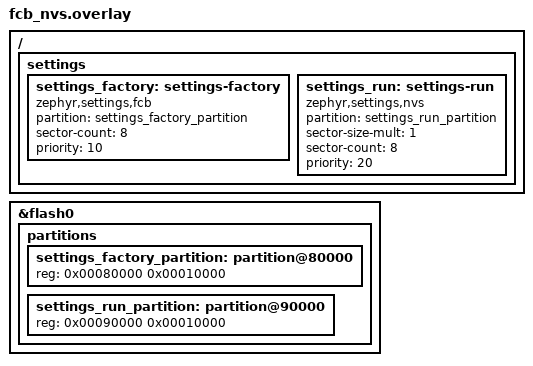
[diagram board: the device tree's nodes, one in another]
/*
 * Copyright (c) 2022 Marcin Niestroj
 *
 * SPDX-License-Identifier: Apache-2.0
 */

/delete-node/ &slot1_partition;

&flash0 {
	partitions {
		settings_factory_partition: partition@80000 {
			reg = <0x00080000 0x00010000>;
		};

		settings_run_partition: partition@90000 {
			reg = <0x00090000 0x00010000>;
		};
	};
};

/ {
	settings {
		settings_factory: settings-factory {
			compatible = "zephyr,settings,fcb";
			partition = <&settings_factory_partition>;
			sector-count = <8>;
			priority = <10>;
		};

		settings_run: settings-run {
			compatible = "zephyr,settings,nvs";
			partition = <&settings_run_partition>;
			sector-size-mult = <1>;
			sector-count = <8>;
			priority = <20>;
		};
	};
};
